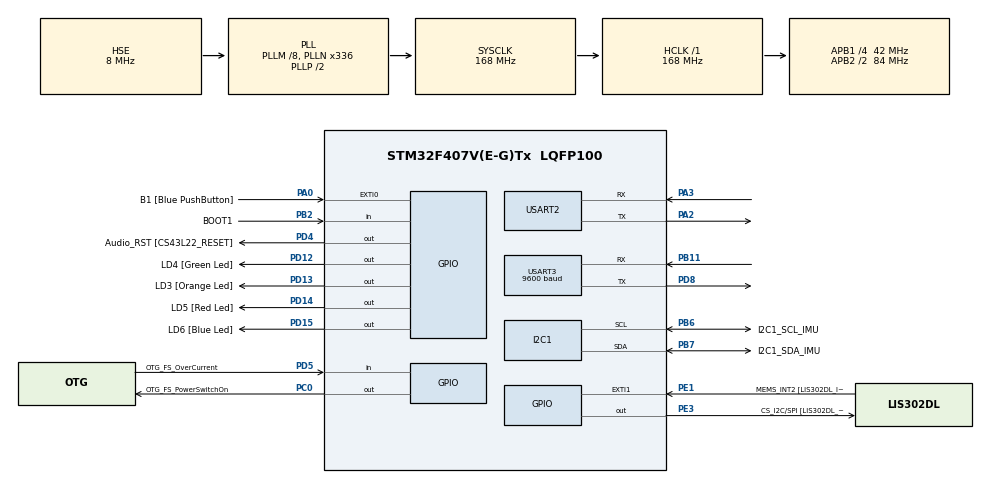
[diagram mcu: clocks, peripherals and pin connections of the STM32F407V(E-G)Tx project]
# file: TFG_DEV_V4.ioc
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Dma.Request0=USART2_RX
Dma.Request1=USART2_TX
Dma.USART2_RX.0.Direction=DMA_PERIPH_TO_MEMORY
Dma.USART2_RX.0.FIFOMode=DMA_FIFOMODE_DISABLE
Dma.USART2_RX.0.Instance=DMA1_Stream5
Dma.USART2_RX.0.MemDataAlignment=DMA_MDATAALIGN_BYTE
Dma.USART2_RX.0.MemInc=DMA_MINC_ENABLE
Dma.USART2_RX.0.Mode=DMA_CIRCULAR
Dma.USART2_RX.0.PeriphDataAlignment=DMA_PDATAALIGN_BYTE
Dma.USART2_RX.0.PeriphInc=DMA_PINC_DISABLE
Dma.USART2_RX.0.Priority=DMA_PRIORITY_LOW
Dma.USART2_TX.1.Direction=DMA_MEMORY_TO_PERIPH
Dma.USART2_TX.1.FIFOMode=DMA_FIFOMODE_DISABLE
Dma.USART2_TX.1.Instance=DMA1_Stream6
Dma.USART2_TX.1.MemDataAlignment=DMA_MDATAALIGN_BYTE
Dma.USART2_TX.1.MemInc=DMA_MINC_ENABLE
Dma.USART2_TX.1.Mode=DMA_NORMAL
Dma.USART2_TX.1.PeriphDataAlignment=DMA_PDATAALIGN_BYTE
Dma.USART2_TX.1.PeriphInc=DMA_PINC_DISABLE
Dma.USART2_TX.1.Priority=DMA_PRIORITY_LOW
FREERTOS.Queues01=imuQueue,10,uint16_t,0,Dynamic,NULL,NULL
FREERTOS.Tasks01=defaultTask,24,128,StartDefaultTask,Default,NULL,Dynamic,NULL,NULL;imuTask,40,256,StartImuTask,Default,NULL,Dynamic,NULL,NULL;wifiTask,32,512,StartWifiTask,Default,NULL,Dynamic,NULL,NULL;systemTask,8,256,StartSystemTask,Default,NULL,Dynamic,NULL,NULL
FREERTOS.configTOTAL_HEAP_SIZE=20000
FREERTOS.configUSE_NEWLIB_REENTRANT=1
I2C1.I2C_Mode=I2C_Fast
Mcu.Family=STM32F4
Mcu.Name=STM32F407V(E-G)Tx
Mcu.Package=LQFP100
NVIC.DMA1_Stream5_IRQn=true\:5\:0\:false\:false\:true\:true\:false\:true\:true
NVIC.DMA1_Stream6_IRQn=true\:5\:0\:false\:false\:true\:true\:false\:true\:true
NVIC.I2C1_EV_IRQn=true\:5\:0\:false\:false\:true\:true\:true\:true\:true
NVIC.PriorityGroup=NVIC_PRIORITYGROUP_4
NVIC.TIM1_UP_TIM10_IRQn=true\:5\:0\:false\:false\:true\:true\:true\:true\:true
NVIC.TIM2_IRQn=true\:15\:0\:false\:false\:true\:false\:false\:true\:true
NVIC.TIM3_IRQn=true\:5\:0\:false\:false\:true\:true\:true\:true\:true
NVIC.TimeBase=TIM2_IRQn
NVIC.TimeBaseIP=TIM2
NVIC.USART2_IRQn=true\:5\:0\:false\:false\:true\:true\:true\:true\:true
NVIC.USART3_IRQn=true\:5\:0\:false\:false\:true\:true\:true\:true\:true
PA0-WKUP.GPIO_Label=B1 [Blue PushButton]
PA0-WKUP.Signal=GPXTI0
PA10.GPIO_Label=OTG_FS_ID
PA10.GPIO_Mode=GPIO_MODE_AF_PP
PA10.GPIO_PuPd=GPIO_NOPULL
PA10.GPIO_Speed=GPIO_SPEED_FREQ_LOW
PA10.Signal=USB_OTG_FS_ID
PA11.GPIO_Label=OTG_FS_DM
PA11.GPIO_Mode=GPIO_MODE_AF_PP
PA11.GPIO_PuPd=GPIO_NOPULL
PA11.GPIO_Speed=GPIO_SPEED_FREQ_LOW
PA11.Signal=USB_OTG_FS_DM
PA12.GPIO_Label=OTG_FS_DP
PA12.GPIO_Mode=GPIO_MODE_AF_PP
PA12.GPIO_PuPd=GPIO_NOPULL
PA12.GPIO_Speed=GPIO_SPEED_FREQ_LOW
PA12.Signal=USB_OTG_FS_DP
PA13.GPIO_Label=SWDIO
PA13.Mode=Serial_Wire
PA13.Signal=SYS_JTMS-SWDIO
PA14.GPIO_Label=SWCLK
PA14.Mode=Serial_Wire
PA14.Signal=SYS_JTCK-SWCLK
PA2.Mode=Asynchronous
PA2.Signal=USART2_TX
PA3.Mode=Asynchronous
PA3.Signal=USART2_RX
PA4.GPIO_Label=I2S3_WS [CS43L22_LRCK]
PA4.GPIO_Mode=GPIO_MODE_AF_PP
PA4.GPIO_PuPd=GPIO_NOPULL
PA4.GPIO_Speed=GPIO_SPEED_FREQ_LOW
PA4.Signal=I2S3_WS
PA5.GPIO_Label=SPI1_SCK [LIS302DL_SCL/SPC]
PA5.GPIO_Mode=GPIO_MODE_AF_PP
PA5.GPIO_PuPd=GPIO_NOPULL
PA5.GPIO_Speed=GPIO_SPEED_FREQ_LOW
PA5.Signal=SPI1_SCK
PA6.GPIO_Label=SPI1_MISO [LIS302DL_SDO]
PA6.GPIO_Mode=GPIO_MODE_AF_PP
PA6.GPIO_PuPd=GPIO_NOPULL
PA6.GPIO_Speed=GPIO_SPEED_FREQ_LOW
PA6.Signal=SPI1_MISO
PA7.GPIO_Label=SPI1_MOSI [LIS302DL_SDA/SDI/SDO]
PA7.GPIO_Mode=GPIO_MODE_AF_PP
PA7.GPIO_PuPd=GPIO_NOPULL
PA7.GPIO_Speed=GPIO_SPEED_FREQ_LOW
PA7.Signal=SPI1_MOSI
PA9.GPIO_Label=VBUS_FS
PA9.GPIO_Mode=GPIO_MODE_INPUT
PA9.GPIO_PuPd=GPIO_NOPULL
PA9.Signal=USB_OTG_FS_VBUS
PB10.GPIO_Label=CLK_IN [MP45DT02_CLK]
PB10.GPIO_Mode=GPIO_MODE_AF_PP
PB10.GPIO_PuPd=GPIO_NOPULL
PB10.GPIO_Speed=GPIO_SPEED_FREQ_LOW
PB10.Signal=I2S2_CK
PB11.Mode=Asynchronous
PB11.Signal=USART3_RX
PB2.GPIO_Label=BOOT1
PB2.GPIO_Mode=GPIO_MODE_INPUT
PB2.GPIO_PuPd=GPIO_NOPULL
PB2.Signal=GPIO_Input
PB3.GPIO_Label=SWO
PB3.Signal=SYS_JTDO-SWO
PB6.GPIO_Label=I2C1_SCL_IMU
PB6.GPIO_Mode=GPIO_MODE_AF_OD
PB6.GPIO_Pu=GPIO_PULLUP
PB6.GPIO_PuPd=GPIO_NOPULL
PB6.GPIO_Speed=GPIO_SPEED_FREQ_LOW
PB6.Mode=I2C
PB6.Signal=I2C1_SCL
PB7.GPIO_Label=I2C1_SDA_IMU
PB7.GPIO_Mode=GPIO_MODE_AF_OD
PB7.GPIO_Pu=GPIO_PULLUP
PB7.GPIO_Speed=GPIO_SPEED_FREQ_LOW
PB7.Mode=I2C
PB7.Signal=I2C1_SDA
PC0.GPIO_Label=OTG_FS_PowerSwitchOn
PC0.GPIO_PuPd=GPIO_NOPULL
PC0.GPIO_Speed=GPIO_SPEED_FREQ_LOW
PC0.PinState=GPIO_PIN_SET
PC0.Signal=GPIO_Output
PC10.GPIO_Label=I2S3_SCK [CS43L22_SCLK]
PC10.GPIO_Mode=GPIO_MODE_AF_PP
PC10.GPIO_PuPd=GPIO_NOPULL
PC10.GPIO_Speed=GPIO_SPEED_FREQ_LOW
PC10.Signal=I2S3_CK
PC12.GPIO_Label=I2S3_SD [CS43L22_SDIN]
PC12.GPIO_Mode=GPIO_MODE_AF_PP
PC12.GPIO_PuPd=GPIO_NOPULL
PC12.GPIO_Speed=GPIO_SPEED_FREQ_LOW
PC12.Signal=I2S3_SD
PC14-OSC32_IN.GPIO_Label=PC14-OSC32_IN
PC14-OSC32_IN.Signal=RCC_OSC32_IN
PC15-OSC32_OUT.GPIO_Label=PC15-OSC32_OUT
PC15-OSC32_OUT.Signal=RCC_OSC32_OUT
PC3.GPIO_Label=PDM_OUT [MP45DT02_DOUT]
PC3.GPIO_Mode=GPIO_MODE_AF_PP
PC3.GPIO_PuPd=GPIO_NOPULL
PC3.GPIO_Speed=GPIO_SPEED_FREQ_LOW
PC3.Signal=I2S2_SD
PC7.GPIO_Label=I2S3_MCK [CS43L22_MCLK]
PC7.GPIO_Mode=GPIO_MODE_AF_PP
PC7.GPIO_PuPd=GPIO_NOPULL
PC7.GPIO_Speed=GPIO_SPEED_FREQ_LOW
PC7.Signal=I2S3_MCK
PD12.GPIO_Label=LD4 [Green Led]
PD12.GPIO_PuPd=GPIO_NOPULL
PD12.GPIO_Speed=GPIO_SPEED_FREQ_LOW
PD12.Signal=GPIO_Output
PD13.GPIO_Label=LD3 [Orange Led]
PD13.GPIO_PuPd=GPIO_NOPULL
PD13.GPIO_Speed=GPIO_SPEED_FREQ_LOW
PD13.Signal=GPIO_Output
PD14.GPIO_Label=LD5 [Red Led]
PD14.GPIO_PuPd=GPIO_NOPULL
PD14.GPIO_Speed=GPIO_SPEED_FREQ_LOW
PD14.Signal=GPIO_Output
PD15.GPIO_Label=LD6 [Blue Led]
PD15.GPIO_PuPd=GPIO_NOPULL
PD15.GPIO_Speed=GPIO_SPEED_FREQ_LOW
PD15.Signal=GPIO_Output
PD4.GPIO_Label=Audio_RST [CS43L22_RESET]
PD4.GPIO_PuPd=GPIO_NOPULL
PD4.GPIO_Speed=GPIO_SPEED_FREQ_LOW
PD4.Signal=GPIO_Output
PD5.GPIO_Label=OTG_FS_OverCurrent
PD5.GPIO_Mode=GPIO_MODE_INPUT
PD5.GPIO_PuPd=GPIO_NOPULL
PD5.Signal=GPIO_Input
PD8.Mode=Asynchronous
PD8.Signal=USART3_TX
PE1.GPIO_Label=MEMS_INT2 [LIS302DL_INT2]
PE1.GPIO_ModeDefaultEXTI=GPIO_MODE_EVT_RISING
PE1.GPIO_PuPd=GPIO_NOPULL
PE1.Signal=GPXTI1
PE3.GPIO_Label=CS_I2C/SPI [LIS302DL_CS_I2C/SPI]
PE3.GPIO_PuPd=GPIO_NOPULL
PE3.GPIO_Speed=GPIO_SPEED_FREQ_LOW
PE3.Signal=GPIO_Output
PH0-OSC_IN.GPIO_Label=PH0-OSC_IN
PH0-OSC_IN.Mode=HSE-External-Oscillator
PH0-OSC_IN.Signal=RCC_OSC_IN
PH1-OSC_OUT.GPIO_Label=PH1-OSC_OUT
PH1-OSC_OUT.Mode=HSE-External-Oscillator
PH1-OSC_OUT.Signal=RCC_OSC_OUT
ProjectManager.HeapSize=0x200
ProjectManager.StackSize=0x400
ProjectManager.TargetToolchain=STM32CubeIDE
RCC.48MHZClocksFreq_Value=48000000
RCC.AHBFreq_Value=168000000
RCC.APB1CLKDivider=RCC_HCLK_DIV4
RCC.APB1Freq_Value=42000000
RCC.APB1TimFreq_Value=84000000
RCC.APB2CLKDivider=RCC_HCLK_DIV2
RCC.APB2Freq_Value=84000000
RCC.APB2TimFreq_Value=168000000
RCC.CortexFreq_Value=168000000
RCC.HCLKFreq_Value=168000000
RCC.HSE_VALUE=8000000
RCC.HSI_VALUE=16000000
RCC.LSE_VALUE=32768
RCC.PLLM=8
RCC.PLLN=336
RCC.PLLQ=7
RCC.PLLSourceVirtual=RCC_PLLSOURCE_HSE
RCC.SYSCLKFreq_VALUE=168000000
RCC.SYSCLKSource=RCC_SYSCLKSOURCE_PLLCLK
RCC.VCOOutputFreq_Value=336000000
TIM1.Period=199
TIM1.Prescaler=16799
TIM3.Period=49
TIM3.Prescaler=16799
USART2.VirtualMode=VM_ASYNC
USART3.BaudRate=9600
USART3.VirtualMode=VM_ASYNC
VP_FREERTOS_VS_CMSIS_V2.Mode=CMSIS_V2
VP_SYS_VS_tim2.Mode=TIM2
VP_TIM1_VS_ClockSourceINT.Mode=Internal
VP_TIM3_VS_ClockSourceINT.Mode=Internal
board=STM32F407G-DISC1

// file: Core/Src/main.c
/* USER CODE BEGIN Header */
/**
  ******************************************************************************
  * @file           : main.c
  * @brief          : Main program body
  ******************************************************************************
  * @attention
  *
  * Copyright (c) 2026 STMicroelectronics.
  * All rights reserved.
  *
  * This software is licensed under terms that can be found in the LICENSE file
  * in the root directory of this software component.
  * If no LICENSE file comes with this software, it is provided AS-IS.
  *
  ******************************************************************************
  */
/* USER CODE END Header */
#include "main.h"
#include "cmsis_os.h"
#include "dma.h"
#include "i2c.h"
#include "tim.h"
#include "usart.h"
#include "gpio.h"
#include "sensors/gps.h"

void SystemClock_Config(void);
void MX_FREERTOS_Init(void);

/* USER CODE BEGIN 0 */
/* Private user code ---------------------------------------------------------*/
/* USER CODE BEGIN 0 */
void HAL_UART_RxCpltCallback(UART_HandleTypeDef *huart)
{
    // Si la interrupción proviene del GPS (UART3)
    if (huart->Instance == USART3)
    {
        GPS_UARTCallback(huart);
    }

    // Si la interrupción proviene del WiFi (UART2)
    // Nota: Aunque el anillo de RX corre por hardware, si el DMA activa
    // flags de transferencia completa, dejamos que la HAL los limpie aquí de forma segura.
    if (huart->Instance == USART2)
    {
        // TODO callback de RX para WiFi por interrupción (si es necesario).
    }
}

// También es vital enrutar las interrupciones de error para evitar que un
// Overrun en el GPS bloquee el WiFi o viceversa
void HAL_UART_ErrorCallback(UART_HandleTypeDef *huart)
{
    if (huart->Instance == USART3)
    {
        // SOLUCIÓN: Llamamos a la API pública limpia para revivir el canal del GPS si se satura
        GPS_RestartReceive();
    }
    if (huart->Instance == USART2)
    {
        HAL_UART_AbortReceive(huart);
    }
}
/* USER CODE END 0 */

/* USER CODE END 0 */

int main(void)
{

  /* MCU Configuration--------------------------------------------------------*/

  /* Reset of all peripherals, Initializes the Flash interface and the Systick. */
  HAL_Init();

  /* Configure the system clock */
  SystemClock_Config();

  /* Initialize all configured peripherals */
  MX_GPIO_Init();
  MX_DMA_Init();
  MX_I2C1_Init();
  MX_TIM1_Init();
  MX_TIM3_Init();
  MX_USART2_UART_Init();
  MX_USART3_UART_Init();

  /* Init scheduler */
  osKernelInitialize();  /* Call init function for freertos objects (in cmsis_os2.c) */
  MX_FREERTOS_Init();

  /* Start scheduler */
  osKernelStart();

  /* We should never get here as control is now taken by the scheduler */

  /* Infinite loop */
  while (1)
  {

  }
}

void SystemClock_Config(void)
{
  RCC_OscInitTypeDef RCC_OscInitStruct = {0};
  RCC_ClkInitTypeDef RCC_ClkInitStruct = {0};

  /** Configure the main internal regulator output voltage
  */
  __HAL_RCC_PWR_CLK_ENABLE();
  __HAL_PWR_VOLTAGESCALING_CONFIG(PWR_REGULATOR_VOLTAGE_SCALE1);

  /** Initializes the RCC Oscillators according to the specified parameters
  * in the RCC_OscInitTypeDef structure.
  */
  RCC_OscInitStruct.OscillatorType = RCC_OSCILLATORTYPE_HSE;
  RCC_OscInitStruct.HSEState = RCC_HSE_ON;
  RCC_OscInitStruct.PLL.PLLState = RCC_PLL_ON;
  RCC_OscInitStruct.PLL.PLLSource = RCC_PLLSOURCE_HSE;
  RCC_OscInitStruct.PLL.PLLM = 8;
  RCC_OscInitStruct.PLL.PLLN = 336;
  RCC_OscInitStruct.PLL.PLLP = RCC_PLLP_DIV2;
  RCC_OscInitStruct.PLL.PLLQ = 7;
  if (HAL_RCC_OscConfig(&RCC_OscInitStruct) != HAL_OK)
  {
    Error_Handler();
  }

  /** Initializes the CPU, AHB and APB buses clocks
  */
  RCC_ClkInitStruct.ClockType = RCC_CLOCKTYPE_HCLK|RCC_CLOCKTYPE_SYSCLK
                              |RCC_CLOCKTYPE_PCLK1|RCC_CLOCKTYPE_PCLK2;
  RCC_ClkInitStruct.SYSCLKSource = RCC_SYSCLKSOURCE_PLLCLK;
  RCC_ClkInitStruct.AHBCLKDivider = RCC_SYSCLK_DIV1;
  RCC_ClkInitStruct.APB1CLKDivider = RCC_HCLK_DIV4;
  RCC_ClkInitStruct.APB2CLKDivider = RCC_HCLK_DIV2;

  if (HAL_RCC_ClockConfig(&RCC_ClkInitStruct, FLASH_LATENCY_5) != HAL_OK)
  {
    Error_Handler();
  }
}

void HAL_TIM_PeriodElapsedCallback(TIM_HandleTypeDef *htim)
{
  if (htim->Instance == TIM2)
  {
    HAL_IncTick();
  }
}

void Error_Handler(void)
{
  __disable_irq();
  while (1)
  {
  }
}

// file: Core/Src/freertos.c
/**
 * @file freertos.c
 * @brief Planificación FreeRTOS de adquisición, empaquetado y envío MQTT de telemetría.
 *
 * @details
 * Este módulo organiza el firmware como una arquitectura desacoplada tipo
 * "data pipeline": cada tarea tiene una responsabilidad única y se comunica con
 * el resto mediante buffers globales protegidos por mutex y flags de estado.
 *
 * La separación entre adquisición, construcción de paquetes y publicación MQTT
 * evita que una operación de red bloquee directamente la lectura de sensores.
 * Esta decisión mejora la robustez temporal del sistema en un entorno embebido
 * donde las comunicaciones WiFi pueden introducir retardos variables.
 *
 * @author Lorenzo
 * @date 14 May 2026
 */

#include "cmsis_os.h"
#include "sensors/sensor10DoF.h"
#include "sensors/gps.h"
#include "communication/wifi.h"
#include "main.h"
#include "common/formatter_data.h"

#include <stdio.h>
#include <string.h>
#include <stdbool.h>

/**
 * @brief UART asociada al módulo WiFi.
 *
 * @details
 * Se declara como externa porque la inicialización física del periférico UART
 * se realiza en el código generado por STM32CubeMX. Este módulo solo necesita
 * la referencia para inicializar y operar el driver WiFi.
 */
extern UART_HandleTypeDef huart2;

/**
 * @brief UART asociada al módulo GPS.
 *
 * @details
 * Se reutiliza el manejador generado por STM32CubeMX para mantener separada la
 * configuración de bajo nivel del periférico y la lógica de adquisición GPS.
 */
extern UART_HandleTypeDef huart3;

/**
 * @def WIFI_TEST_SSID
 * @brief SSID de la red WiFi usada por el sistema durante la ejecución.
 *
 * @details
 * Se mantiene como macro para simplificar la configuración de conexión en un
 * entorno embebido sin almacenamiento persistente de credenciales.
 */
#define WIFI_TEST_SSID      ""

/**
 * @def WIFI_TEST_PASS
 * @brief Contraseña de la red WiFi usada por el sistema durante la ejecución.
 */
#define WIFI_TEST_PASS      ""

/**
 * @def SERVER_HOST
 * @brief Dirección IP del broker MQTT local.
 *
 * @details
 * El uso de dirección IP directa evita depender de resolución DNS en el módulo
 * WiFi y reduce una posible fuente de fallo durante las pruebas locales.
 */
#define SERVER_HOST         ""

/**
 * @def PAYLOAD_LENGHT
 * @brief Tamaño reservado para cada payload JSON de telemetría.
 *
 * @details
 * El valor se dimensiona para mensajes MQTT compactos, reduciendo consumo de
 * RAM sin recurrir a reserva dinámica de memoria.
 */
#define PAYLOAD_LENGHT 128

/**
 * @brief Última lectura válida del sensor IMU/10DoF.
 *
 * @details
 * Actúa como buffer compartido entre la tarea de adquisición IMU y la tarea de
 * empaquetado. Su acceso se protege mediante @ref imuMutex.
 */
static Sensor10DoF_t imu_data;

/**
 * @brief Paquete de telemetría GPS preparado para serialización.
 */
static GpsDataPacket_t gpsPacket;

/**
 * @brief Paquete de telemetría inercial preparado para serialización.
 */
static ImuDataPacket_t imuPacket;

/**
 * @brief Paquete de telemetría ambiental preparado para serialización.
 */
static EnvDataPacket_t envPacket;

/**
 * @brief Buffer JSON del paquete GPS pendiente de envío.
 *
 * @details
 * Se usa un buffer estático para evitar fragmentación de memoria y mantener un
 * comportamiento determinista en FreeRTOS.
 */
static char payload_gpsPacket[PAYLOAD_LENGHT]={0};

/**
 * @brief Buffer JSON del paquete IMU pendiente de envío.
 *
 * @details
 * El buffer queda desacoplado del paquete binario para que la tarea WiFi pueda
 * copiar una versión estable antes de publicar por MQTT.
 */
static char payload_imuPacket[PAYLOAD_LENGHT]={0};

/**
 * @brief Buffer JSON del paquete ambiental pendiente de envío.
 */
static char payload_envPacket[PAYLOAD_LENGHT]={0};

/**
 * @brief Indica que existe una nueva muestra IMU disponible para empaquetado.
 *
 * @details
 * Permite desacoplar la frecuencia de lectura del sensor de la frecuencia de
 * construcción de paquetes sin bloquear la tarea de adquisición más tiempo del
 * necesario.
 */
static uint8_t imuDataUpdated = 0;

/**
 * @brief Indica que existe una nueva muestra GPS disponible para empaquetado.
 */
static uint8_t gpsDataUpdated = 0;

/**
 * @brief Solicita reconstruir los paquetes derivados de la última muestra IMU.
 */
static uint8_t imuPacketToUpdate = 0;

/**
 * @brief Solicita reconstruir el paquete derivado de la última muestra GPS.
 */
static uint8_t gpsPacketToUpdate = 0;

/**
 * @brief Indica que el payload IMU/ambiental está listo para publicación MQTT.
 */
static uint8_t imuPacketToSend = 0;

/**
 * @brief Indica que el payload GPS está listo para publicación MQTT.
 */
static uint8_t gpsPacketToSend = 0;

/**
 * @brief Último estado reportado por el driver WiFi.
 *
 * @details
 * Se declara como volatile porque su valor representa estado externo del módulo
 * de comunicaciones y se consulta de forma recurrente desde la tarea WiFi.
 */
volatile wifi_status_t wifi_st;

/**
 * @brief Último estado reportado por el driver GPS.
 *
 * @details
 * Se conserva global para facilitar diagnóstico y reutilización del estado de
 * inicialización del módulo GPS.
 */
volatile gps_status_t gps_st;

/**
 * @brief Mutex de protección para el buffer compartido de datos IMU.
 */
osMutexId_t imuMutex;

/**
 * @brief Mutex de protección para el buffer compartido de datos GPS.
 */
osMutexId_t gpsMutex;

/**
 * @brief Mutex de protección para payloads JSON y flags de publicación.
 */
osMutexId_t packetMutex;

/**
 * @brief Handle de la tarea de adquisición IMU.
 */
osThreadId_t imuTaskHandle;

/**
 * @brief Handle de la tarea de adquisición GPS.
 */
osThreadId_t gpsTaskHandle;

/**
 * @brief Handle de la tarea de construcción de paquetes de telemetría.
 */
osThreadId_t packetTaskHandle;

/**
 * @brief Handle de la tarea de conexión WiFi y publicación MQTT.
 */
osThreadId_t wifiTaskHandle;

/**
 * @brief Atributos RTOS de la tarea de adquisición IMU.
 *
 * @details
 * La pila se dimensiona con margen para las llamadas al driver 10DoF y la
 * prioridad normal permite que tareas de comunicación puedan ejecutarse sin
 * bloquear indefinidamente la adquisición.
 */
const osThreadAttr_t imuTask_attributes =
{
    .name = "imuTask",
    .stack_size = 1024 * 4,
    .priority = (osPriority_t) osPriorityNormal
};

/**
 * @brief Atributos RTOS de la tarea WiFi/MQTT.
 *
 * @details
 * La prioridad superior reduce el riesgo de acumulación de payloads cuando la
 * publicación MQTT necesita atenderse con rapidez frente a tareas de menor
 * criticidad temporal.
 */
const osThreadAttr_t wifiTask_attributes =
{
    .name = "wifiTask",
    .stack_size = 1024 * 4,
    .priority = (osPriority_t) osPriorityAboveNormal
};

/**
 * @brief Atributos RTOS de la tarea GPS.
 *
 * @details
 * El GPS se ejecuta con menor prioridad porque su frecuencia útil de actualización
 * es inferior a la de la IMU y no requiere una cadencia tan estricta.
 */
const osThreadAttr_t gpsTask_attributes =
{
    .name = "gpsTask",
    .stack_size = 512 * 4,
    .priority = (osPriority_t) osPriorityBelowNormal
};

/**
 * @brief Atributos RTOS de la tarea de empaquetado.
 *
 * @details
 * Su prioridad superior permite transformar datos recientes en payloads JSON con
 * baja latencia antes de que la tarea WiFi los publique.
 */
const osThreadAttr_t packetTask_attributes =
{
    .name = "packetTask",
    .stack_size = 1024 * 4,
    .priority = (osPriority_t) osPriorityAboveNormal
};

/**
 * @brief Tarea FreeRTOS de adquisición del sensor IMU/10DoF.
 *
 * @param argument Argumento genérico proporcionado por CMSIS-RTOS. No se utiliza.
 *
 * @details
 * Inicializa el sensor y mantiene actualizada la última muestra disponible. Si
 * una lectura falla, se solicita un reset del sensor para recuperar el bus o el
 * estado interno del driver sin detener el resto del sistema.
 *
 * La tarea solo mantiene bloqueado el mutex durante la sección crítica de lectura
 * y actualización del buffer compartido. Esto reduce la contención con la tarea
 * de empaquetado.
 */
void StartImuTask(void *argument)
{
    Sensor10DoF_Init();

    for(;;)
    {
        osMutexAcquire(imuMutex, osWaitForever);

        if(Sensor10DoF_Read(&imu_data) != SENSOR_OK)
        {
            Sensor10DoF_Reset();
        }else{
        	imuDataUpdated = 1;
        }
        osMutexRelease(imuMutex);

        osDelay(100);
    }
}

/**
 * @brief Tarea FreeRTOS de inicialización y procesado periódico del GPS.
 *
 * @param argument Argumento genérico proporcionado por CMSIS-RTOS. No se utiliza.
 *
 * @details
 * Reintenta la inicialización del GPS hasta obtener un estado válido. Este patrón
 * evita que un arranque lento del módulo GPS impida la ejecución del resto del
 * firmware.
 *
 * Durante la ejecución periódica, la tarea procesa la entrada NMEA/UART mediante
 * el driver GPS y marca la muestra como disponible para la etapa de empaquetado.
 */
void StartGpsTask(void *argument)
{

	gps_st = GPS_Init(&huart3);

    while(gps_st != GPS_OK)
    {
    	gps_st = GPS_Init(&huart3);
        osDelay(100);
    }

    for(;;)
    {
        osMutexAcquire(gpsMutex, osWaitForever);
        GPS_Process();
        gpsDataUpdated = 1;
        osMutexRelease(gpsMutex);

        osDelay(500);
    }
}

/**
 * @brief Tarea FreeRTOS de fusión lógica y serialización de telemetría.
 *
 * @param argument Argumento genérico proporcionado por CMSIS-RTOS. No se utiliza.
 *
 * @details
 * Esta tarea actúa como etapa intermedia entre adquisición y comunicación. Copia
 * muestras recientes bajo mutex, libera rápidamente los recursos compartidos y
 * construye los paquetes fuera de las secciones críticas siempre que sea posible.
 *
 * El diseño evita que la generación de JSON o la publicación MQTT accedan
 * directamente a las estructuras internas de los drivers, reduciendo acoplamiento
 * y facilitando cambios de formato en la telemetría.
 */
void StartPacketTask(void *argument)
{

    static Sensor10DoF_t imu;
    static gps_data_t gps;

    GpsDataPacket_Init(&gpsPacket);
    ImuDataPacket_Init(&imuPacket);
    EnvDataPacket_Init(&envPacket);

    for(;;)
    {
        osMutexAcquire(imuMutex, osWaitForever);
        if(imuDataUpdated)
        {
            imu = imu_data;
            imuDataUpdated = 0;
            imuPacketToUpdate = 1;
        }
        osMutexRelease(imuMutex);

        osMutexAcquire(gpsMutex, osWaitForever);
        if(gpsDataUpdated)
        {
        	gps = GPS_GetData();
        	gpsDataUpdated = 0;
        	gpsPacketToUpdate = 1;
        }
        osMutexRelease(gpsMutex);

        if(imuPacketToUpdate)
        {
			imuPacket.accel[0] = imu.accel_x_ms2;
			imuPacket.accel[1] = imu.accel_y_ms2;
			imuPacket.accel[2] = imu.accel_z_ms2;

			imuPacket.gyro[0] = imu.gyro_x_dps;
			imuPacket.gyro[1] = imu.gyro_y_dps;
			imuPacket.gyro[2] = imu.gyro_z_dps;

			imuPacket.mag[0] = imu.heading_deg;
			imuPacket.mag[1] = imu.roll_deg;
			imuPacket.mag[2] = imu.pitch_deg;

			envPacket.heading = imu.heading_deg;
			envPacket.temperature = imu.temperature_c;
			envPacket.pressure = imu.pressure_hpa;
        }

        if(gpsPacketToUpdate){
			gpsPacket.altitude = gps.altitude;
			gpsPacket.latitude = gps.latitude;
			gpsPacket.longitude = gps.longitude;

        }

        osMutexAcquire(packetMutex, osWaitForever);
        if(imuPacketToUpdate)
        {
			ImuData_to_json(payload_imuPacket,
					sizeof(payload_imuPacket),
					&imuPacket);

			EnvData_to_json(payload_envPacket,
					sizeof(payload_envPacket),
					&envPacket);

			imuPacketToUpdate = 0;
			imuPacketToSend = 1;
        }

        if(gpsPacketToUpdate)
        {
			GpsData_to_json(payload_gpsPacket,
					sizeof(payload_gpsPacket),
					&gpsPacket);

			gpsPacketToUpdate = 0;
			gpsPacketToSend = 1;
        }

        osMutexRelease(packetMutex);

        osDelay(50);
    }
}

/**
 * @brief Tarea FreeRTOS de conexión WiFi y publicación MQTT.
 *
 * @param argument Argumento genérico proporcionado por CMSIS-RTOS. No se utiliza.
 *
 * @details
 * Inicializa el módulo WiFi, garantiza la conexión al punto de acceso y configura
 * una sesión MQTT antes de entrar en el bucle de publicación.
 *
 * Los payloads se copian a buffers temporales antes de llamar al driver WiFi para
 * minimizar el tiempo de bloqueo de @ref packetMutex. Esta decisión evita que una
 * publicación lenta impida a la tarea de empaquetado actualizar nuevos mensajes.
 */
void StartWifiTask(void *argument)
{
	static char payload_gpsTemp[PAYLOAD_LENGHT]={0};
	static char payload_imuTemp[PAYLOAD_LENGHT]={0};
	static char payload_envTemp[PAYLOAD_LENGHT]={0};

    wifi_st = WIFI_Init(&huart2);
    osDelay(1000);

    while(wifi_st != WIFI_OK)
    {
    	wifi_st = WIFI_Reset();
        wifi_st = WIFI_Init(&huart2);
        osDelay(1000);
    }
    wifi_st = WIFI_ConnectAP(WIFI_TEST_SSID, WIFI_TEST_PASS);
    osDelay(1000);

    while(wifi_st != WIFI_OK)
    {
    	wifi_st = WIFI_ConnectAP(WIFI_TEST_SSID, WIFI_TEST_PASS);
        osDelay(1000);
    }

    WIFI_MQTT_Disconnect();
    osDelay(500);

    wifi_st = WIFI_MQTT_UserConfig("stm32_client");
    osDelay(500);

    wifi_st = WIFI_MQTT_Connect(SERVER_HOST, 1883);
    osDelay(500);

    for(;;)
    {
        if(gpsPacketToSend)
        {
            osMutexAcquire(packetMutex, osWaitForever);

            strcpy(payload_gpsTemp, payload_gpsPacket);

            osMutexRelease(packetMutex);

            wifi_st = WIFI_MQTT_Publish("telemetry",payload_gpsTemp,0,0);

            gpsPacketToSend = 0;

            osDelay(10);

        }

        if(imuPacketToSend)
        {
            osMutexAcquire(packetMutex, osWaitForever);

            strcpy(payload_imuTemp, payload_imuPacket);

            osMutexRelease(packetMutex);

            wifi_st = WIFI_MQTT_Publish("telemetry",payload_imuTemp,0,0);
            osDelay(10);

            osMutexAcquire(packetMutex, osWaitForever);

            strcpy(payload_envTemp, payload_envPacket);

            osMutexRelease(packetMutex);

            wifi_st = WIFI_MQTT_Publish("telemetry",payload_envTemp,0,0);

            imuPacketToSend = 0;

        }

		if(wifi_st != WIFI_OK)
		{
		}

        osDelay(50);
    }
}

/**
 * @brief Inicializa los recursos FreeRTOS definidos por la aplicación.
 *
 * @details
 * Crea los mutex compartidos y lanza las tareas que forman la cadena de
 * adquisición, empaquetado y transmisión. La función conserva el patrón esperado
 * por STM32CubeMX para integrarse con la inicialización global del proyecto.
 */
void MX_FREERTOS_Init(void)
{
    imuMutex = osMutexNew(NULL);
    gpsMutex = osMutexNew(NULL);
    packetMutex = osMutexNew(NULL);

    imuTaskHandle = osThreadNew(StartImuTask,NULL,&imuTask_attributes);
    gpsTaskHandle = osThreadNew(StartGpsTask,NULL,&gpsTask_attributes);
    wifiTaskHandle = osThreadNew(StartWifiTask,NULL,&wifiTask_attributes);
    packetTaskHandle = osThreadNew(StartPacketTask,NULL,&packetTask_attributes);

}
